# HK32F0301MxxC register map
Vendor: HKMicroChip Ltd.; Series: HK32F0301MxxC; File version: 0.9
CPU: CM0 r0p0, little endian, no MPU, no FPU, 3 interrupt priority bits
Registers are 32-bit, read-write, reset 0x0 unless marked. A register's access mark holds for its fields unless they carry their own. Offsets are from the block's base; [hi:lo] are bit positions; {n}, {i} and the like mark numbered series.

## GPIOA
Base 0x48000000
Same registers: GPIOC 0x48000800
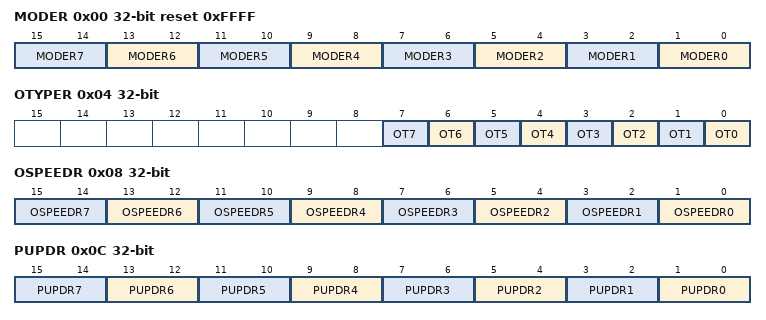
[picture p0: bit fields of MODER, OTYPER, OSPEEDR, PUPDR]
0x00 MODER reset 0xFFFF
  [2n+1:2n] MODER{n} (n=0..7) — Port x pin y mode configuration bits
0x04 OTYPER
  [n] OT{n} (n=0..7) — Port x pin y output type configuration bits
0x08 OSPEEDR
  [2n+1:2n] OSPEEDR{n} (n=0..7) — Port x pin y output speed configuration bits
0x0C PUPDR
  [2n+1:2n] PUPDR{n} (n=0..7) — Port x pin y pull-up/down configuration bits
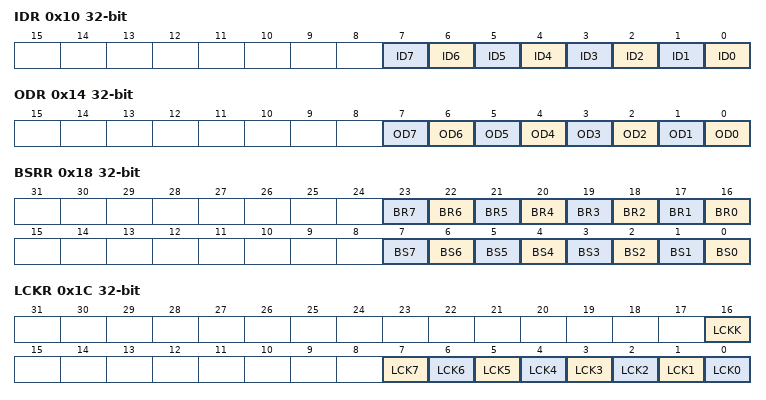
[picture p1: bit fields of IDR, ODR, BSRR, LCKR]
0x10 IDR ro
  [n] ID{n} (n=0..7) — Port x pin y input data
0x14 ODR
  [n] OD{n} (n=0..7) — Port x pin y output data
0x18 BSRR wo
  [n+16] BR{n} (n=0..7) — Port x reset bit y
  [n] BS{n} (n=0..7) — Port x set bit y
0x1C LCKR
  [16] LCKK — Lock key
  [n] LCK{n} (n=0..7) — Port x pin y lock bit y
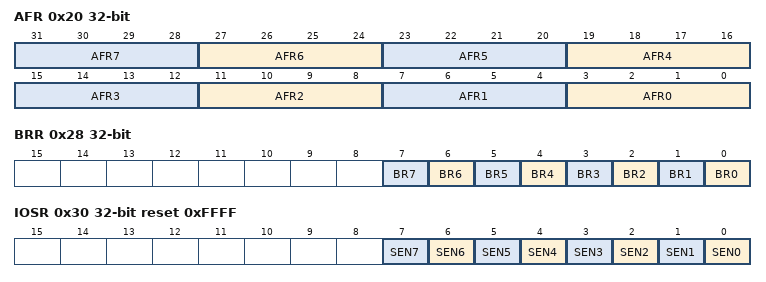
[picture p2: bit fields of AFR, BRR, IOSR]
0x20 AFR
  [4n+3:4n] AFR{n} (n=0..7) — Alternate function selection bits for port x pin y
0x28 BRR wo
  [n] BR{n} (n=0..7) — Port x pin y reset bit y
0x30 IOSR reset 0xFFFF
  [n] SEN{n} (n=0..7) — Port x pin y Schmitt switch

## GPIOB
Base 0x48000400
Same registers: GPIOD 0x48000C00
Registers as GPIOA; these are added or differ:
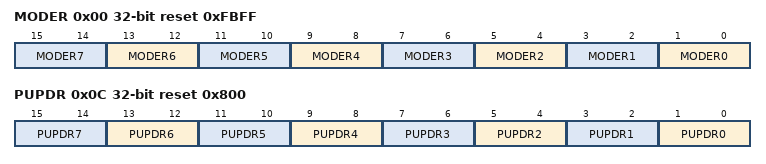
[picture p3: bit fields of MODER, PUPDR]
0x00 MODER reset 0xFBFF
  [2n+1:2n] MODER{n} (n=0..7) — Port x pin y mode configuration bits
0x0C PUPDR reset 0x800
  [2n+1:2n] PUPDR{n} (n=0..7) — Port x pin y pull-up/down configuration bits

## IOMUX
Base 0x40017C00
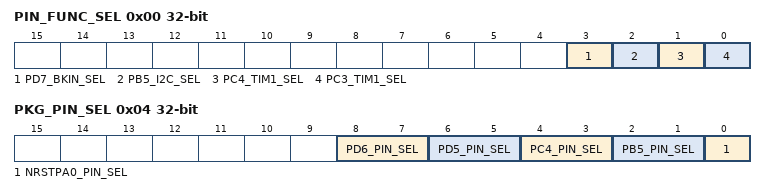
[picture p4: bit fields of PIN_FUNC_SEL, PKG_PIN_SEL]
0x00 PIN_FUNC_SEL
  [3] PD7_BKIN_SEL — Pin functional selection for PD5
  [2] PB5_I2C_SEL — Pin functional selection for PB5
  [1] PC4_TIM1_SEL — Pin functional selection for PC4
  [0] PC3_TIM1_SEL — Pin functional selection for PC3
0x04 PKG_PIN_SEL
  [8:7] PD6_PIN_SEL — Pin MUX for PD6
  [6:5] PD5_PIN_SEL — Pin MUX for PD5
  [4:3] PC4_PIN_SEL — Pin MUX for PC4
  [2:1] PB5_PIN_SEL — Pin MUX for PB5
  [0] NRSTPA0_PIN_SEL — Pin MUX for NRST
0x08 NRST_PIN_KEY
  [15:0] NRST_PIN_KEY — The key of pin NRST change to PA0
0x0C NRST_PA0_SEL
  [0] NRST_PA0_SEL — Pin Functional Selection for NRST/PA0

## EXTI
Base 0x40010400
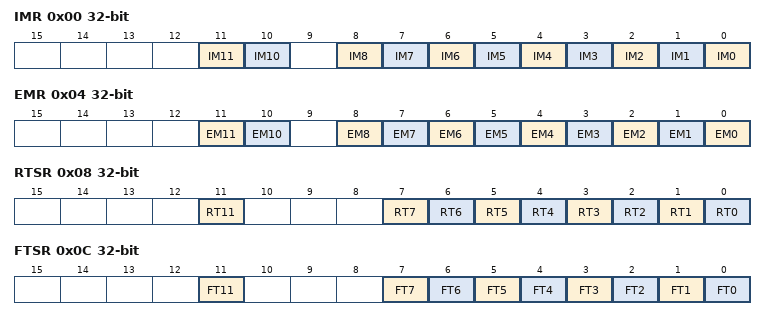
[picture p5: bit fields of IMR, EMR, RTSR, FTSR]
0x00 IMR
  [11] IM11 — Interrupt mask on line x
  [10] IM10 — Interrupt mask on line x
  [n] IM{n} (n=0..8) — Interrupt mask on line x
0x04 EMR
  [11] EM11 — Event mask on line x
  [10] EM10 — Event mask on line x
  [n] EM{n} (n=0..8) — Event mask on line x
0x08 RTSR
  [11] RT11 — Rising trigger event configuration bit of line 11
  [n] RT{n} (n=0..7) — Rising trigger event configuration bit of line x
0x0C FTSR
  [11] FT11 — Falling trigger event configuration bit of line 11
  [n] FT{n} (n=0..7) — Falling trigger event configuration bit of line x
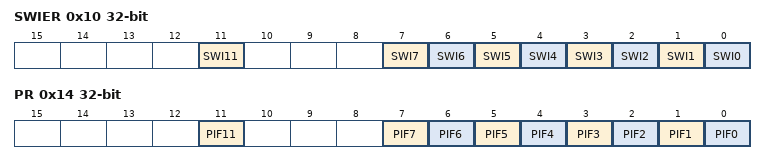
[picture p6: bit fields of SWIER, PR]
0x10 SWIER
  [11] SWI11 — Software interrupt on line 11
  [n] SWI{n} (n=0..7) — Software interrupt on line x
0x14 PR
  [11] PIF11 — Pending interrupt flag on line 11
  [n] PIF{n} (n=0..7) — Pending interrupt flag on line x

## ADC
Base 0x40012400
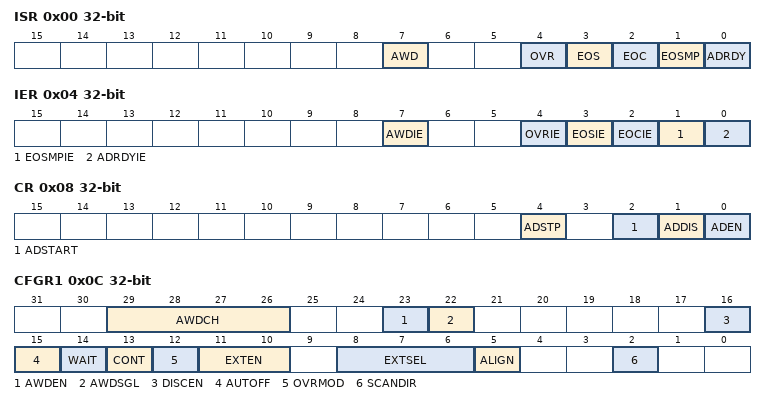
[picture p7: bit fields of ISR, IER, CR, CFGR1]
0x00 ISR
  [7] AWD — End of calibration flag
  [4] OVR — ADC overrun
  [3] EOS — End of sequence flag
  [2] EOC — End of conversion flag
  [1] EOSMP — End of sampling flag
  [0] ADRDY — ADC ready
0x04 IER
  [7] AWDIE — Analog watchdog interrupt enable
  [4] OVRIE — Overrun interrupt enable
  [3] EOSIE — End of conversion sequence interrupt enable
  [2] EOCIE — End of conversion interrupt enable
  [1] EOSMPIE — End of sampling flag interrupt enable
  [0] ADRDYIE — ADC ready interrupt enable
0x08 CR
  [4] ADSTP — ADC stop conversion command
  [2] ADSTART — ADC start conversion command
  [1] ADDIS — ADC disable command
  [0] ADEN — ADC enable command
0x0C CFGR1
  [29:26] AWDCH — Analog watchdog channel selection
  [23] AWDEN — Analog watchdog enable
  [22] AWDSGL — Enable the watchdog on a single channel or on all channels
  [16] DISCEN — Discontinuous mode
  [15] AUTOFF — Auto-off mode
  [14] WAIT — Wait conversion mode
  [13] CONT — Single/continuous conversion mode
  [12] OVRMOD — Overrun management mode
  [11:10] EXTEN — External trigger enable and polarity selection
  [8:6] EXTSEL — External trigger selection
  [5] ALIGN — Data alignment
  [2] SCANDIR — Scan sequence direction
0x10 CFGR2
  [31:30] CKMODE — ADC clock mode
0x14 SMPR
  [2:0] SMP — Sampling time selection
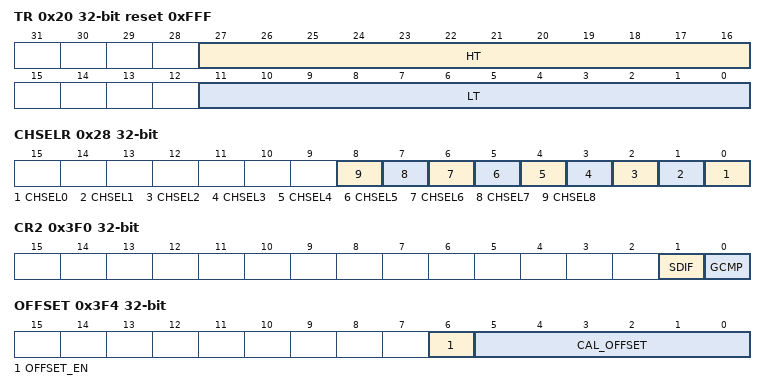
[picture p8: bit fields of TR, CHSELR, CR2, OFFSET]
0x20 TR reset 0xFFF
  [27:16] HT — Analog watchdog higher threshold
  [11:0] LT — Analog watchdog lower threshold
0x28 CHSELR
  [n] CHSEL{n} (n=0..8) — Channel-x selection
0x40 DR ro
  [15:0] DATA — Converted data
0x308 CCR
  [22] VREFEN — VREFINT enable
{0x3C0+4i} DR{i} ro (i=0..8)
  [11:0] DRx — Channel x latest converted data
0x3F0 CR2
  [1] SDIF — Differential input enable
  [0] GCMP — ADC internal delay control
0x3F4 OFFSET
  [6] OFFSET_EN — Calibration Offset enable
  [5:0] CAL_OFFSET — ADC Calibration Offset data
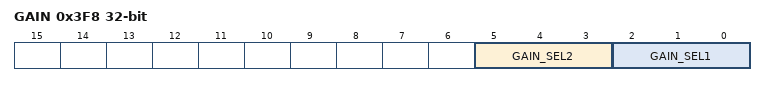
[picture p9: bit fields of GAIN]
0x3F8 GAIN
  [5:3] GAIN_SEL2 — Gain calibration factor 2 selection
  [2:0] GAIN_SEL1 — Gain calibration factor 1 selection
